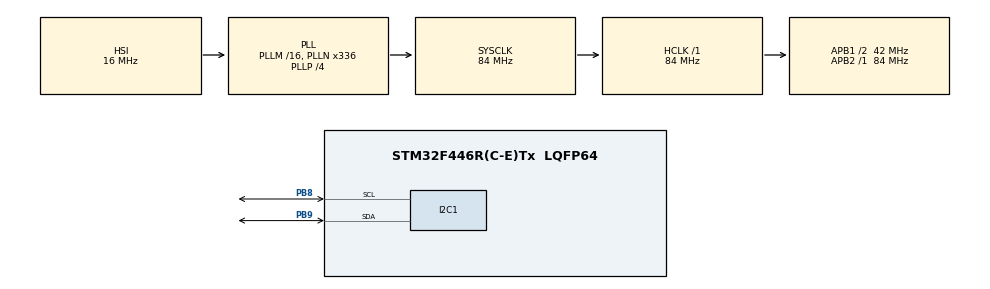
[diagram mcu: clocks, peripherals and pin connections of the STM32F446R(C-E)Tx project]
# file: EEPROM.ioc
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I2C1.I2C_Mode=I2C_Fast
Mcu.Family=STM32F4
Mcu.Name=STM32F446R(C-E)Tx
Mcu.Package=LQFP64
NVIC.I2C1_ER_IRQn=true\:0\:0\:false\:false\:true\:true\:true\:true
NVIC.I2C1_EV_IRQn=true\:0\:0\:false\:false\:true\:true\:true\:true
NVIC.PriorityGroup=NVIC_PRIORITYGROUP_0
PA13.Mode=Serial_Wire
PA13.Signal=SYS_JTMS-SWDIO
PA14.Mode=Serial_Wire
PA14.Signal=SYS_JTCK-SWCLK
PB8.Mode=I2C
PB8.Signal=I2C1_SCL
PB9.Mode=I2C
PB9.Signal=I2C1_SDA
PH0-OSC_IN.Mode=HSE-External-Oscillator
PH0-OSC_IN.Signal=RCC_OSC_IN
PH1-OSC_OUT.Mode=HSE-External-Oscillator
PH1-OSC_OUT.Signal=RCC_OSC_OUT
ProjectManager.HeapSize=0x200
ProjectManager.StackSize=0x400
ProjectManager.TargetToolchain=STM32CubeIDE
RCC.48MHZClocksFreq_Value=84000000
RCC.AHBFreq_Value=84000000
RCC.APB1CLKDivider=RCC_HCLK_DIV2
RCC.APB1Freq_Value=42000000
RCC.APB1TimFreq_Value=84000000
RCC.APB2Freq_Value=84000000
RCC.APB2TimFreq_Value=84000000
RCC.CortexFreq_Value=84000000
RCC.FLatency-AdvancedSettings=FLASH_LATENCY_2
RCC.HCLKFreq_Value=84000000
RCC.HSE_VALUE=8000000
RCC.HSI_VALUE=16000000
RCC.PLLN=336
RCC.PLLP=RCC_PLLP_DIV4
RCC.SYSCLKFreq_VALUE=84000000
RCC.SYSCLKSource=RCC_SYSCLKSOURCE_PLLCLK
RCC.USBFreq_Value=168000000
RCC.VCOOutputFreq_Value=336000000
board=NUCLEO-F446RE

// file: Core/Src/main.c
/* USER CODE BEGIN Header */
/* USER CODE END Header */
#include "main.h"

/* USER CODE BEGIN Includes */
#include "string.h"
#include "EEPROM.h"
#include "stdio.h"
/* USER CODE END Includes */

I2C_HandleTypeDef hi2c1;

/* USER CODE BEGIN PV */
struct data
{
	char seconds;
	char minutes;
	char hour;
	char dayofweek;
	char dayofmonth;
	char month;
	char year;
	float adc1_value;
	float adc2_value;
	float adc3_value;
	float adc4_value;
	float MDS_value;
	uint8_t GPIO[4];
	uint8_t scan_time;
	char Status1[5];
	char Status2[5];
	char Status3[5];
	char Status4[5];
};

struct data d;

/* USER CODE END PV */

void SystemClock_Config(void);
static void MX_GPIO_Init(void);
static void MX_I2C1_Init(void);
/* USER CODE BEGIN PFP */
void Data_To_EEPROM(char *eeprom_data);

/* USER CODE END PFP */

/* USER CODE BEGIN 0 */

uint8_t DataRead[650];
char eeprom_data[200];
static uint8_t page_number = 0;  // Start with page 0
uint8_t offset = 0;       // Start with offset 0

/* USER CODE END 0 */

int main(void)
{

	/* MCU Configuration--------------------------------------------------------*/

	/* Reset of all peripherals, Initializes the Flash interface and the Systick. */
	HAL_Init();

	/* Configure the system clock */
	SystemClock_Config();

	/* Initialize all configured peripherals */
	MX_GPIO_Init();
	MX_I2C1_Init();
	/* USER CODE BEGIN 2 */

	d.seconds=59;
	d.minutes=21;
	d.hour=12;
	d.dayofweek=4;
	d.dayofmonth=27;
	d.month=11;
	d.year=24;
	d.adc1_value=24.34;
	d.adc2_value=25.34;
	d.adc3_value=26.34;
	d.adc4_value=27.34;
	d.MDS_value=19.53;
	strcpy(d.Status1, "HIGH");
	strcpy(d.Status2, "LOW");
	strcpy(d.Status3, "HIGH");
	strcpy(d.Status4, "HIGH");
	sprintf((char *)eeprom_data,"Time:%02d:%02d:%02d,Date:%02d:%02d:%02d,CH1:%.2f,CH2:%.2f,CH3:%.2f,CH4:%.2f,MDS:%.2f,Status1:%s,Status2:%s,Status3:%s,Status4:%s",
			d.hour, d.minutes, d.seconds,d.dayofmonth, d.month, d.year,
			d.adc1_value, d.adc2_value, d.adc3_value, d.adc4_value,
			d.MDS_value, d.Status1, d.Status2, d.Status3, d.Status4);

	for (int i=0; i<512; i++)
	{
		EEPROM_PageErase(i);
	}

	//	EEPROM_Read(0,0,DataRead,500);
	//	HAL_I2C_Mem_Read(&hi2c1, 0xA0, (3<<6), 2, DataRead, 64, 1000);
	for(int i=0;i<3;i++)
	{
		Data_To_EEPROM(eeprom_data);
	}

	//	EEPROM_Write(0,0,(uint8_t*)eeprom_data,strlen(eeprom_data));
	//	EEPROM_Write(2,32,(uint8_t*)eeprom_data,strlen(eeprom_data));
	//	EEPROM_Write(5,0,(uint8_t*)eeprom_data,strlen(eeprom_data));
	//	EEPROM_Write(7,32,(uint8_t*)eeprom_data,strlen(eeprom_data));

	EEPROM_Read(0,0,DataRead,650);
	//EEPROM_Read(1,0,DataRead,200);
	//EEPROM_Write(3,0,(uint8_t*)eeprom_data,strlen(eeprom_data));

	/* USER CODE END 2 */

	/* Infinite loop */
	while (1)
	{

	}
}

void SystemClock_Config(void)
{
	RCC_OscInitTypeDef RCC_OscInitStruct = {0};
	RCC_ClkInitTypeDef RCC_ClkInitStruct = {0};

	/** Configure the main internal regulator output voltage
	 */
	__HAL_RCC_PWR_CLK_ENABLE();
	__HAL_PWR_VOLTAGESCALING_CONFIG(PWR_REGULATOR_VOLTAGE_SCALE3);

	/** Initializes the RCC Oscillators according to the specified parameters
	 * in the RCC_OscInitTypeDef structure.
	 */
	RCC_OscInitStruct.OscillatorType = RCC_OSCILLATORTYPE_HSI;
	RCC_OscInitStruct.HSIState = RCC_HSI_ON;
	RCC_OscInitStruct.HSICalibrationValue = RCC_HSICALIBRATION_DEFAULT;
	RCC_OscInitStruct.PLL.PLLState = RCC_PLL_ON;
	RCC_OscInitStruct.PLL.PLLSource = RCC_PLLSOURCE_HSI;
	RCC_OscInitStruct.PLL.PLLM = 16;
	RCC_OscInitStruct.PLL.PLLN = 336;
	RCC_OscInitStruct.PLL.PLLP = RCC_PLLP_DIV4;
	RCC_OscInitStruct.PLL.PLLQ = 2;
	RCC_OscInitStruct.PLL.PLLR = 2;
	if (HAL_RCC_OscConfig(&RCC_OscInitStruct) != HAL_OK)
	{
		Error_Handler();
	}

	/** Initializes the CPU, AHB and APB buses clocks
	 */
	RCC_ClkInitStruct.ClockType = RCC_CLOCKTYPE_HCLK|RCC_CLOCKTYPE_SYSCLK
			|RCC_CLOCKTYPE_PCLK1|RCC_CLOCKTYPE_PCLK2;
	RCC_ClkInitStruct.SYSCLKSource = RCC_SYSCLKSOURCE_PLLCLK;
	RCC_ClkInitStruct.AHBCLKDivider = RCC_SYSCLK_DIV1;
	RCC_ClkInitStruct.APB1CLKDivider = RCC_HCLK_DIV2;
	RCC_ClkInitStruct.APB2CLKDivider = RCC_HCLK_DIV1;

	if (HAL_RCC_ClockConfig(&RCC_ClkInitStruct, FLASH_LATENCY_2) != HAL_OK)
	{
		Error_Handler();
	}
}

static void MX_I2C1_Init(void)
{

	hi2c1.Instance = I2C1;
	hi2c1.Init.ClockSpeed = 400000;
	hi2c1.Init.DutyCycle = I2C_DUTYCYCLE_2;
	hi2c1.Init.OwnAddress1 = 0;
	hi2c1.Init.AddressingMode = I2C_ADDRESSINGMODE_7BIT;
	hi2c1.Init.DualAddressMode = I2C_DUALADDRESS_DISABLE;
	hi2c1.Init.OwnAddress2 = 0;
	hi2c1.Init.GeneralCallMode = I2C_GENERALCALL_DISABLE;
	hi2c1.Init.NoStretchMode = I2C_NOSTRETCH_DISABLE;
	if (HAL_I2C_Init(&hi2c1) != HAL_OK)
	{
		Error_Handler();
	}

}

static void MX_GPIO_Init(void)
{

	/* GPIO Ports Clock Enable */
	__HAL_RCC_GPIOH_CLK_ENABLE();
	__HAL_RCC_GPIOA_CLK_ENABLE();
	__HAL_RCC_GPIOB_CLK_ENABLE();

}

/* USER CODE BEGIN 4 */

void Data_To_EEPROM(char *eeprom_data)
{

	EEPROM_Write(page_number,offset,(uint8_t*)eeprom_data,strlen(eeprom_data));
	page_number+=3;
}

/* USER CODE END 4 */

void Error_Handler(void)
{
}
